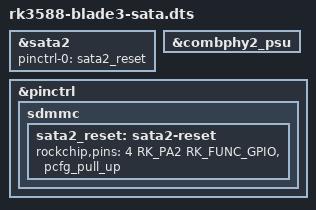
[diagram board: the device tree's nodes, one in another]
// SPDX-License-Identifier: (GPL-2.0+ OR MIT)
/*
 * Copyright (c) 2022 Mixtile Limited
 *
 */

/dts-v1/;

#include "rk3588-blade3.dts"

&sata2 {
	pinctrl-names = "default";
	pinctrl-0 = <&sata2_reset>;
	status = "okay";
};

&combphy2_psu {
	status = "okay";
};

&pinctrl {
	sdmmc {
		sata2_reset: sata2-reset {
			rockchip,pins = <4 RK_PA2 RK_FUNC_GPIO &pcfg_pull_up>;
		};
	};
};
